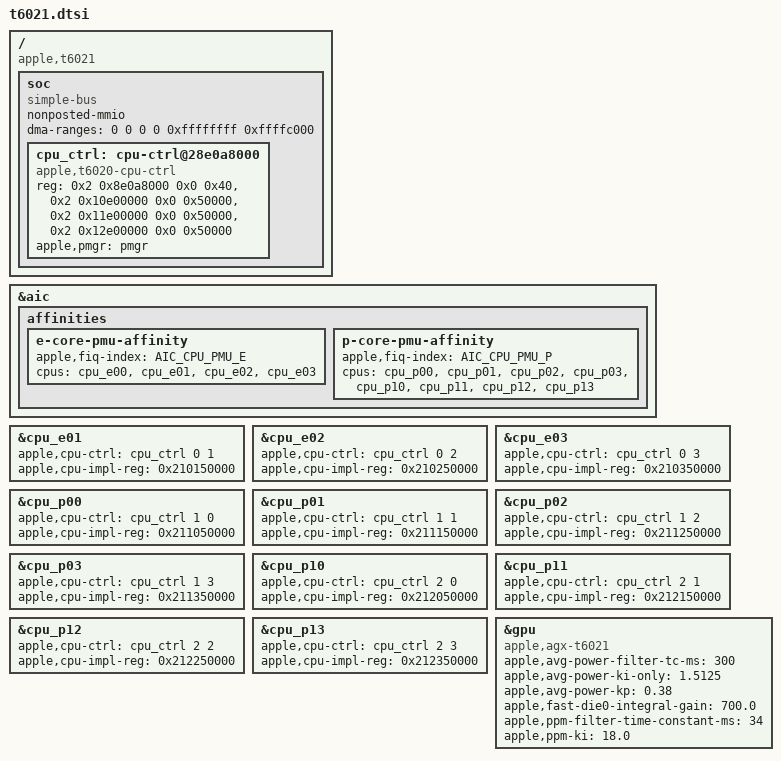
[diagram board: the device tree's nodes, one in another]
// SPDX-License-Identifier: GPL-2.0+ OR MIT
/*
 * Apple T6021 "M2 Max" SoC
 *
 * Other names: H14J, "Rhodes"
 *
 * Copyright The Asahi Linux Contributors
 */

#include <dt-bindings/gpio/gpio.h>
#include <dt-bindings/interrupt-controller/apple-aic.h>
#include <dt-bindings/interrupt-controller/irq.h>
#include <dt-bindings/pinctrl/apple.h>
#include <dt-bindings/phy/phy.h>
#include <dt-bindings/spmi/spmi.h>

#include "multi-die-cpp.h"

#ifndef GPU_REPEAT
# define GPU_REPEAT(x) <x x x x>
#endif
#ifndef GPU_DIE_REPEAT
# define GPU_DIE_REPEAT(x) <x>
#endif

#define APPLE_T602X_NON_ULTRA

#include "t602x-common.dtsi"

/ {
	compatible = "apple,t6021", "apple,arm-platform";

	soc {
		compatible = "simple-bus";
		#address-cells = <2>;
		#size-cells = <2>;

		ranges;
		nonposted-mmio;
		/* Required to get >32-bit DMA via DARTs */
		dma-ranges = <0 0 0 0 0xffffffff 0xffffc000>;

		// filled via templated includes at the end of the file
	};
};

#define DIE
#define DIE_NO 0

&{/soc} {
	#include "t602x-die0.dtsi"
	#include "t602x-dieX.dtsi"
	#include "t602x-nvme.dtsi"
};

#include "t602x-gpio-pins.dtsi"
#include "t602x-pmgr.dtsi"

#undef DIE
#undef DIE_NO


&aic {
	affinities {
		e-core-pmu-affinity {
			apple,fiq-index = <AIC_CPU_PMU_E>;
			cpus = <&cpu_e00 &cpu_e01 &cpu_e02 &cpu_e03>;
		};

		p-core-pmu-affinity {
			apple,fiq-index = <AIC_CPU_PMU_P>;
			cpus = <&cpu_p00 &cpu_p01 &cpu_p02 &cpu_p03
				&cpu_p10 &cpu_p11 &cpu_p12 &cpu_p13>;
		};
	};
};

/*
 * PMGR CPU start/stop controls and the CPU complex registers of each
 * cluster; the cluster power states live in the PMGR. They let secondary
 * CPUs go offline and come back. The boot CPU has no such description: it
 * cannot be restarted.
 */
&{/soc} {
	cpu_ctrl: cpu-ctrl@28e0a8000 {
		compatible = "apple,t6020-cpu-ctrl";
		reg = <0x2 0x8e0a8000 0x0 0x40>,
			<0x2 0x10e00000 0x0 0x50000>,
			<0x2 0x11e00000 0x0 0x50000>,
			<0x2 0x12e00000 0x0 0x50000>;
		reg-names = "cpu-start", "acc0", "acc1", "acc2";
		apple,pmgr = <&pmgr>;
	};
};

&cpu_e01 {
	apple,cpu-ctrl = <&cpu_ctrl 0 1>;
	apple,cpu-impl-reg = /bits/ 64 <0x210150000>;
};

&cpu_e02 {
	apple,cpu-ctrl = <&cpu_ctrl 0 2>;
	apple,cpu-impl-reg = /bits/ 64 <0x210250000>;
};

&cpu_e03 {
	apple,cpu-ctrl = <&cpu_ctrl 0 3>;
	apple,cpu-impl-reg = /bits/ 64 <0x210350000>;
};

&cpu_p00 {
	apple,cpu-ctrl = <&cpu_ctrl 1 0>;
	apple,cpu-impl-reg = /bits/ 64 <0x211050000>;
};

&cpu_p01 {
	apple,cpu-ctrl = <&cpu_ctrl 1 1>;
	apple,cpu-impl-reg = /bits/ 64 <0x211150000>;
};

&cpu_p02 {
	apple,cpu-ctrl = <&cpu_ctrl 1 2>;
	apple,cpu-impl-reg = /bits/ 64 <0x211250000>;
};

&cpu_p03 {
	apple,cpu-ctrl = <&cpu_ctrl 1 3>;
	apple,cpu-impl-reg = /bits/ 64 <0x211350000>;
};

&cpu_p10 {
	apple,cpu-ctrl = <&cpu_ctrl 2 0>;
	apple,cpu-impl-reg = /bits/ 64 <0x212050000>;
};

&cpu_p11 {
	apple,cpu-ctrl = <&cpu_ctrl 2 1>;
	apple,cpu-impl-reg = /bits/ 64 <0x212150000>;
};

&cpu_p12 {
	apple,cpu-ctrl = <&cpu_ctrl 2 2>;
	apple,cpu-impl-reg = /bits/ 64 <0x212250000>;
};

&cpu_p13 {
	apple,cpu-ctrl = <&cpu_ctrl 2 3>;
	apple,cpu-impl-reg = /bits/ 64 <0x212350000>;
};

&gpu {
	compatible = "apple,agx-t6021", "apple,agx-g14x", "apple,agx-g14c", "apple,agx-g14s";

	apple,avg-power-filter-tc-ms = <300>;
	apple,avg-power-ki-only = <1.5125>;
	apple,avg-power-kp = <0.38>;
	apple,fast-die0-integral-gain = <700.0>;
	apple,ppm-filter-time-constant-ms = <34>;
	apple,ppm-ki = <18.0>;
};
